# cslr_imcop_001 register map
Vendor: Texas Instruments
Peripheral module from a debugger description file.
Registers are 32-bit, read-only, reset 0x0 unless marked. A register's access mark holds for its fields unless they carry their own. Offsets are as the file gives them; lines under a group give offsets from that group; [hi:lo] are bit positions; {n}, {i} and the like mark numbered series; 'fields as' and 'values as' point back to an identical list; <NAME> marks a mode.

## IMCOP — Imaging Coprocessors
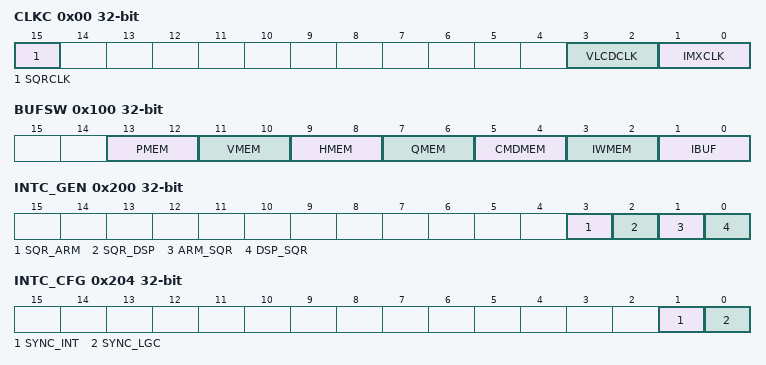
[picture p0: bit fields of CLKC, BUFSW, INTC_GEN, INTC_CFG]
0x00 CLKC access per field — Clock controller
  [15] SQRCLK rw — Sequencer clock control
    0=DISABLE; 1=ENABLE
  [3:2] VLCDCLK rw — VLCD clock control
    0=DISABLE; 1=ENABLEALWAYS; 2=ENABLEWHENOPERATING
  [1:0] IMXCLK rw — iMX clock control
    0=DISABLE
{0x4+4i} RSV0_{i} (i=0..62) — Reserved
  [31:0] RSV
0x100 BUFSW access per field — Buffer switch
  [13:12] PMEM rw — Sequencer Program Memory multiplexer switch
    0=CPDMABUS; 1=SEQUENCER; 2=DEPENDSONSQR_RUN
  [11:10] VMEM rw — VLCD Working Memory Vmem multiplexer switch
    0=CPDMABUS; 1=VLCD; 2=DEPENDSONVLCD_BUSY
  [9:8] HMEM rw — VLCD Huffman Memory Hmem multiplexer switch
    0=CPDMABUS; 1=VLCD; 2=DEPENDSONVLCD_BUSY
  [7:6] QMEM rw — VLCD QIQ Memory Qmem multiplexer switch
    0=CPDMABUS; 1=VLCD; 2=DEPENDSONVLCD_BUSY
  [5:4] CMDMEM rw — IMX Command Memory Cmdmem multiplexer switch
    0=CPDMABUS; 1=IMX; 2=DEPENDSONIMX_BUSY
  [3:2] IWMEM rw — IMX Working Memory Iwmem multiplexer switch
    0=CPDMABUS; 1=IMX; 2=DEPENDSONIMX_BUSY
  [1:0] IBUF rw — Image buffer multiplexer switch
    0=CPDMA_LOWER_IMX_UPPER (cpdma bus gets lower half, iMX gets upper half); 1=CPDMA_UPPER_IMX_LOWER (cpdma bus gets upper half, iMX gets lower half)
{0x104+4i} RSV1_{i} (i=0..62) — Reserved
  [31:0] RSV
0x200 INTC_GEN access per field — Interrupt generation
  [3] SQR_ARM wo — Writing 1 generates an interrupt pulse from sequencer to ARM
  [2] SQR_DSP wo — Writing 1 generates an interrupt pulse from sequencer to DSP
  [1] ARM_SQR wo — Writing 1 generates an interrupt pulse from ARM to sequencer
  [0] DSP_SQR wo — Writing 1 generates an interrupt pulse from DSP to sequencer
0x204 INTC_CFG access per field — Sequencer interrupt controller configuration
  [1] SYNC_INT rw — Sequencer in sync or interrupt mode
    0=SYNC; 1=INTERRUPT
  [0] SYNC_LGC rw — \hSequencer sync logic mode. This applies only to sync mode, and has no effect on interrupt mode. Interrupts are always logically ORed.
    0=LOGICALAND; 1=LOGICALOR
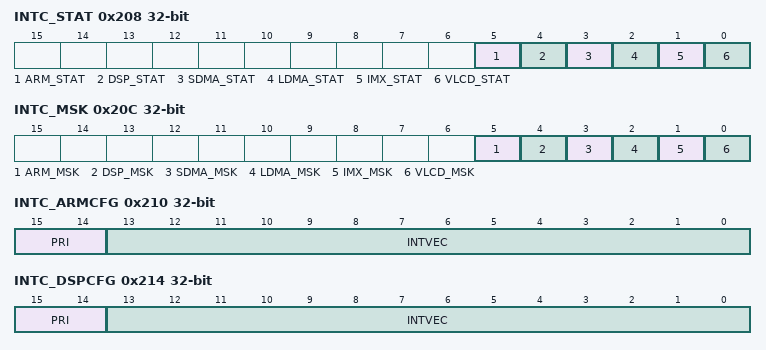
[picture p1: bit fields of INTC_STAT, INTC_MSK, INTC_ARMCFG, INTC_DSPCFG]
0x208 INTC_STAT access per field — Sequencer interrupt or sync state
  [5] ARM_STAT rw — \hStatus of interrupt from ARM to sequencer read 0 = hasn't occurred read 1 = has occurred write 0 = no effect write 1 = clear status
  [4] DSP_STAT rw — \hStatus of interrupt from DSP to sequencer read 0 = hasn't occurred read 1 = has occurred write 0 = no effect write 1 = clear status
  [3] SDMA_STAT rw — \hStatus of interrupt from system DMA to sequencer read 0 = hasn't occurred read 1 = has occurred write 0 = no effect write 1 = clear status
  [2] LDMA_STAT rw — \hStatus of interrupt from local DMA to sequencer read 0 = hasn't occurred read 1 = has occurred write 0 = no effect write 1 = clear status
  [1] IMX_STAT rw — \hStatus of interrupt from iMX read 0 = hasn't occurred read 1 = has occurred write 0 = no effect write 1 = clear status
  [0] VLCD_STAT rw — \hStatus of interrupt from VLCD read 0 = hasn't occurred read 1 = has occurred write 0 = no effect write 1 = clear status
0x20C INTC_MSK access per field — Sequencer sync/interrupt mask
  [5] ARM_MSK rw — Sync/interrupt mask of interrupt from ARM to sequencer
    0=DISABLE; 1=ENABLE
  [4] DSP_MSK rw — Sync/interrupt mask of interrupt from DSP to sequencer
  [3] SDMA_MSK rw — Sync/interrupt mask of interrupt from system DMA to sequencer
    0=DISABLE; 1=ENABLE
  [2] LDMA_MSK rw — Sync/interrupt mask of interrupt from local DMA to sequencer
    0=DISABLE; 1=ENABLE
  [1] IMX_MSK rw — Sync/interrupt mask of interrupt from iMX
    0=DISABLE; 1=ENABLE
  [0] VLCD_MSK rw — Sync/interrupt mask of interrupt from VLCD
    0=DISABLE; 1=ENABLE
0x210 INTC_ARMCFG access per field — ARM-to-sequencer interrupt configuration
  [15:14] PRI rw — Interrupt priority, 0 = lowest, 3 = highest
  [13:0] INTVEC rw — Interrupt vector sent to sequencer for this interrupt
0x214 INTC_DSPCFG access per field — DSP-to-sequencer interrupt configuration
  fields as INTC_ARMCFG
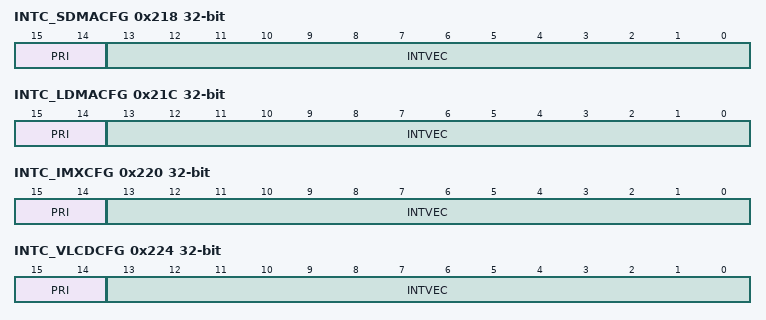
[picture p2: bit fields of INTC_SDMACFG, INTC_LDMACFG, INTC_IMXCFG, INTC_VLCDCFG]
0x218 INTC_SDMACFG access per field — System DMA-to-sequencer interrupt configuration
  fields as INTC_ARMCFG
0x21C INTC_LDMACFG access per field — Local DMA-to-sequencer interrupt configuration
  fields as INTC_ARMCFG
0x220 INTC_IMXCFG access per field — iMX-to-sequencer interrupt configuration
  fields as INTC_ARMCFG
0x224 INTC_VLCDCFG access per field — VLCD-to-sequencer interrupt configuration
  fields as INTC_ARMCFG
0x228 RSV2 — Reserved
  [31:0] RSV
0x22C RSV3 — Reserved
  [31:0] RSV
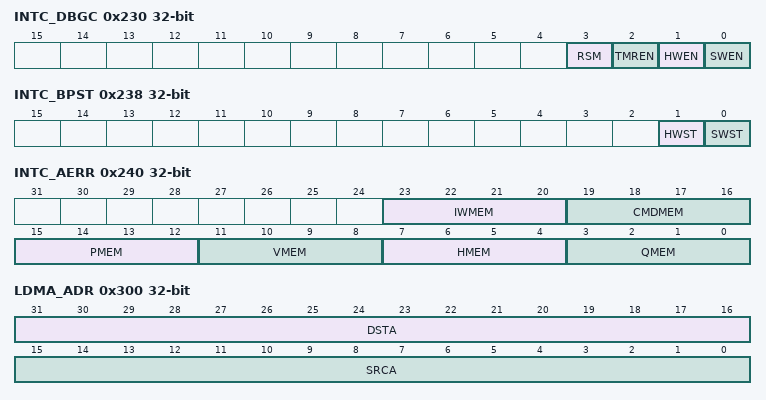
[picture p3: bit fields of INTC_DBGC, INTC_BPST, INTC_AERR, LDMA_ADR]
0x230 INTC_DBGC access per field — Sequencer debug control
  [3] RSM wo — \hResume from pause. Writing 1 resumes sequencer execution from hardware/software breakpoint pause
  [2] TMREN rw — Performance timer enable
    0=DISABLE; 1=ENABLE
  [1] HWEN rw — Hardware breakpoint enable
    0=DISABLE; 1=ENABLE
  [0] SWEN rw — Software breakpoint enable
    0=DISABLE; 1=ENABLE
0x234 INTC_HWBPA access per field — Sequencer hardware breakpoint address
  [15:0] BPA rw — \hHardware breakpoint relative to pmem. When sequencer accesses this location for program fetch, a hardware breakpoint is triggered.
0x238 INTC_BPST — Sequencer breakpoint status
  [1] HWST — Sequencer paused from hardware breakpoint
  [0] SWST — Sequencer paused from software breakpoint
0x23C INTC_TMR access per field — Sequencer performance timer
  [15:0] CNT rw — \hTimer Count. Value of free-running timer, running at sequencer clock to facilitate profiling and performance tuning. Writing any value will restart counting from that value.
0x240 INTC_AERR access per field — Memory access error status
  [all] fields
    0=NO_ERROR; 1=GEM_UMAP; 2=SYSTEM_CFG (System CFG Bus); 3=SEQ_DAP (Sequencer Data Access Port); 4=SEQ_PAP (Sequencer Program Access Port); 5=IMX; 6=VLCD; 7=LDMA
  [23:20] IWMEM rw — \hIwmem access error status. 0 = no error, nonzero host_id = illegal access originated from the host write any value to clear
  [19:16] CMDMEM rw — \hCmdmem access error status. 0 = no error, nonzero host_id = illegal access originated from the host write any value to clear
  [15:12] PMEM rw — \hPmem access error status. 0 = no error, nonzero host_id = illegal access originated from the host write any value to clear
  [11:8] VMEM rw — \hVmem access error status. 0 = no error, nonzero host_id = illegal access originated from the host write any value to clear
  [7:4] HMEM rw — \hHmem access error status. 0 = no error, nonzero host_id = illegal access originated from the host write any value to clear
  [3:0] QMEM rw — \hQmem access error status. 0 = no error, nonzero host_id = illegal access originated from the host write any value to clear
{0x244+4i} RSV4_{i} (i=0..46) — Reserved
  [31:0] RSV
0x300 LDMA_ADR rw — Local DMA address
  [31:16] DSTA — Destination address for local DMA, in sequencer memory map
  [15:0] SRCA — Source address for local DMA, in sequencer memory map
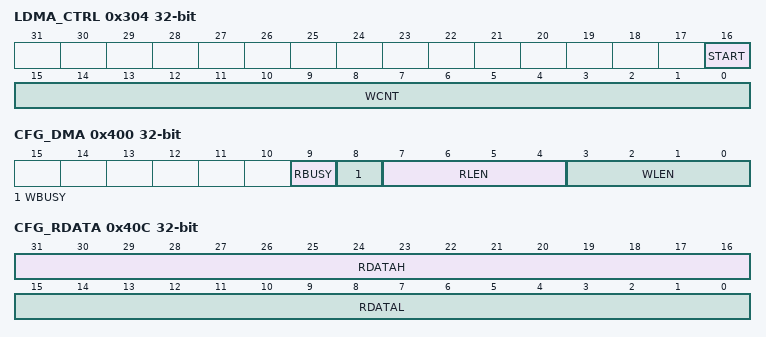
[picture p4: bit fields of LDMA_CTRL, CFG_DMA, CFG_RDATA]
0x304 LDMA_CTRL access per field — Local DMA control
  [16] START rw — \hLDMA DMA Start/Status. Write any value to start DMA. Read back completion status. 0 = idle/complete. 1 = busy
  [15:0] WCNT rw — \hWord count. 16-bit/word writing nonzero value starts DMA
{0x308+4i} RSV5_{i} (i=0..61) — Reserved
  [31:0] RSV
0x400 CFG_DMA access per field — System CFG bus DMA setup
  [9] RBUSY ro — Read request status
    0=DONE_IDLE; 1=BUSY
  [8] WBUSY ro — Write request status
    0=DONE_IDLE; 1=BUSY
  [7:4] RLEN ro — \hRead request length. Will read RLEN+1 16-bit words
  [3:0] WLEN rw — \hWrite request length. Will write WLEN+1 16-bit words
0x404 CFG_RADDR rw — System CFG bus read address
  [31:0] CFG_RADDR — \hAddress submitted to system CFG bus for read. The address stored here is used as the address to request a read on the system CFG bus. This is for the Sequencer, with its 16-bit address space, to access system CFG bus, which has 32-bit address space.
0x408 CFG_WADDR rw — Systen CFG bus write address
  [31:0] CFG_WADDR — \hAddress submitted to system CFG bus for read. The address stored here is used as the address to request a write on the system CFG bus. This is for the 16-bit address space sequencer to access system CFG bus which has 32-bit address space. Note that t
0x40C CFG_RDATA — CFG bus request read data
  [31:16] RDATAH — \hCFG bus request read data, upper 16-bit. Reading this word extracts data from the Read FIFO. When the Read FIFO is empty, reading this word will return undefined value. Data is extracted lowest-addressed-word first.
  [15:0] RDATAL — \hCFG bus request read data, lower 16-bit. Reading this word extracts data from the Read FIFO. When the Read FIFO is empty, reading this word will return undefined value. Data is extracted lowest-addressed-word first.
0x410 CFG_WDATA — CFG bus request write data
  [15:0] WDATA — \hCFG bus request write data. Writing to this register fills the Write FIFO. When the Write FIFO is full, subsequent writes will be ignored.
